AUTOSAR XML (schema 00048)
package /VehicleProject
  system System
    system mapping System_MPPNG
      data-mappings:
        data-element=Sig_Light_1_Ctrl.Sig_Light_1_Ctrl, system-signal=Sig_Light_1_Ctrl
        data-element=Sig_Light_1_Sts.Sig_Light_1_Sts, system-signal=Sig_Light_1_Sts
    root-software-compositions:
      root sw composition prototype EcuSwComposition: software-composition=ECU_Composition
package /ECUCompositionTypes
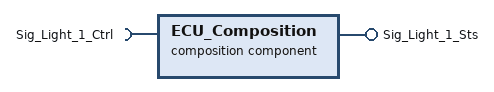
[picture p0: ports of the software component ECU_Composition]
  composition sw component type ECU_Composition
    require port Sig_Light_1_Ctrl: nonqueued-receiver-com-spec{data-element=Sig_Light_1_Ctrl, init-value=0}, required-interface=Sig_Light_1_Ctrl
    provide port Sig_Light_1_Sts: nonqueued-sender-com-spec{data-element=Sig_Light_1_Sts, init-value=0}, provided-interface=Sig_Light_1_Sts
    component ECU_APPM: type=ECU_APPM
    delegate ECU_APPM.Sig_Light_1_Ctrl <-> outer port Sig_Light_1_Ctrl
    delegate ECU_APPM.Sig_Light_1_Sts <-> outer port Sig_Light_1_Sts
package /EndToEndProtections
  end to end protection set EndToEndProtectionSet
